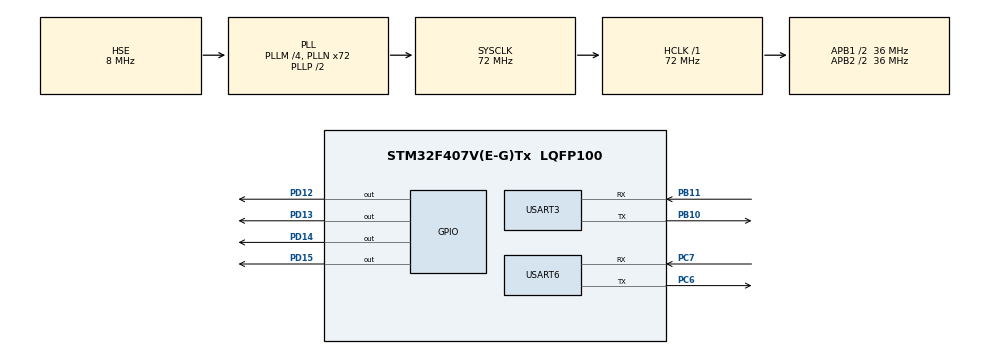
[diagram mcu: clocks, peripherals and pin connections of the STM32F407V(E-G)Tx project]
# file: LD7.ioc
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Mcu.Family=STM32F4
Mcu.Name=STM32F407V(E-G)Tx
Mcu.Package=LQFP100
NVIC.PriorityGroup=NVIC_PRIORITYGROUP_0
NVIC.TIM2_IRQn=true\:0\:0\:false\:true\:true\:3\:true\:true\:true
NVIC.USART3_IRQn=true\:0\:0\:false\:true\:true\:1\:true\:true\:true
NVIC.USART6_IRQn=true\:0\:0\:false\:true\:true\:2\:true\:true\:true
PA13.Mode=Trace_Asynchronous_SW
PA13.Signal=SYS_JTMS-SWDIO
PA14.Mode=Trace_Asynchronous_SW
PA14.Signal=SYS_JTCK-SWCLK
PB10.Mode=Asynchronous
PB10.Signal=USART3_TX
PB11.Mode=Asynchronous
PB11.Signal=USART3_RX
PB3.Mode=Trace_Asynchronous_SW
PB3.Signal=SYS_JTDO-SWO
PC6.Mode=Asynchronous
PC6.Signal=USART6_TX
PC7.Mode=Asynchronous
PC7.Signal=USART6_RX
PD12.Signal=GPIO_Output
PD13.Signal=GPIO_Output
PD14.Signal=GPIO_Output
PD15.Signal=GPIO_Output
PH0-OSC_IN.Mode=HSE-External-Clock-Source
PH0-OSC_IN.Signal=RCC_OSC_IN
PH1-OSC_OUT.Mode=HSE-External-Clock-Source
PH1-OSC_OUT.Signal=RCC_OSC_OUT
ProjectManager.HeapSize=0x200
ProjectManager.StackSize=0x400
ProjectManager.TargetToolchain=STM32CubeIDE
RCC.48MHZClocksFreq_Value=20571428.57142857
RCC.AHBFreq_Value=72000000
RCC.APB1CLKDivider=RCC_HCLK_DIV2
RCC.APB1Freq_Value=36000000
RCC.APB1TimFreq_Value=72000000
RCC.APB2CLKDivider=RCC_HCLK_DIV2
RCC.APB2Freq_Value=36000000
RCC.APB2TimFreq_Value=72000000
RCC.CortexFreq_Value=72000000
RCC.HCLKFreq_Value=72000000
RCC.HSE_VALUE=8000000
RCC.HSI_VALUE=16000000
RCC.PLLM=4
RCC.PLLN=72
RCC.PLLQ=7
RCC.PLLSourceVirtual=RCC_PLLSOURCE_HSE
RCC.SYSCLKFreq_VALUE=72000000
RCC.SYSCLKSource=RCC_SYSCLKSOURCE_PLLCLK
RCC.VCOOutputFreq_Value=144000000
TIM2.Period=2000
TIM2.Prescaler=36000-1
USART3.VirtualMode=VM_ASYNC
USART6.VirtualMode=VM_ASYNC
VP_TIM2_VS_ClockSourceINT.Mode=Internal
board=STM32F407G-DISC1

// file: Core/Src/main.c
/* USER CODE BEGIN Header */
/**
  ******************************************************************************
  * @file           : main.c
  * @brief          : Main program body
  ******************************************************************************
  * @attention
  *
  * Copyright (c) 2024 STMicroelectronics.
  * All rights reserved.
  *
  * This software is licensed under terms that can be found in the LICENSE file
  * in the root directory of this software component.
  * If no LICENSE file comes with this software, it is provided AS-IS.
  *
  ******************************************************************************
  */
/* USER CODE END Header */
#include "main.h"

TIM_HandleTypeDef htim2;

UART_HandleTypeDef huart3;
UART_HandleTypeDef huart6;

void SystemClock_Config(void);
static void MX_GPIO_Init(void);
static void MX_USART3_UART_Init(void);
static void MX_USART6_UART_Init(void);
static void MX_TIM2_Init(void);
static void MX_NVIC_Init(void);

int main(void)
{

  /* MCU Configuration--------------------------------------------------------*/

  /* Reset of all peripherals, Initializes the Flash interface and the Systick. */
  HAL_Init();

  /* Configure the system clock */
  SystemClock_Config();

  /* Initialize all configured peripherals */
  MX_GPIO_Init();
  MX_USART3_UART_Init();
  MX_USART6_UART_Init();
  MX_TIM2_Init();

  /* Initialize interrupts */
  MX_NVIC_Init();
  /* USER CODE BEGIN 2 */
  HAL_TIM_Base_Start_IT(&htim2);
  uint8_t txData[] = {0x01,0x03,0x07,0x0F};
  uint8_t rxData;
  uint8_t i = 0;
  /* USER CODE END 2 */

  /* Infinite loop */
  /* USER CODE BEGIN WHILE */
  while (1)
  {
//	  if(i<3){
//	 	  i ++;
//	 	  }else
//	 	  {
//	 		  i = 0;
//	 	  }
//
//
//	         HAL_UART_Transmit(&huart3, &txData[i], 1, 1000);
//	  HAL_UART_Receive(&huart6, &rxData, 1, 8);
//	         // Transmit received data via USART6
//	       //  HAL_GPIO_TogglePin(GPIOD, GPIO_PIN_12);
//	         GPIOD->ODR &= 0x00000000;
//	         GPIOD->ODR |= (rxData << 12);
//	         HAL_Delay(1000);
//	  if(rxData == 0xFF)
//	  {
//		  HAL_GPIO_TogglePin(GPIOD, GPIO_PIN_15);
//	  }
    /* USER CODE END WHILE */

  }
}

void SystemClock_Config(void)
{
  RCC_OscInitTypeDef RCC_OscInitStruct = {0};
  RCC_ClkInitTypeDef RCC_ClkInitStruct = {0};

  /** Configure the main internal regulator output voltage
  */
  __HAL_RCC_PWR_CLK_ENABLE();
  __HAL_PWR_VOLTAGESCALING_CONFIG(PWR_REGULATOR_VOLTAGE_SCALE1);

  /** Initializes the RCC Oscillators according to the specified parameters
  * in the RCC_OscInitTypeDef structure.
  */
  RCC_OscInitStruct.OscillatorType = RCC_OSCILLATORTYPE_HSE;
  RCC_OscInitStruct.HSEState = RCC_HSE_BYPASS;
  RCC_OscInitStruct.PLL.PLLState = RCC_PLL_ON;
  RCC_OscInitStruct.PLL.PLLSource = RCC_PLLSOURCE_HSE;
  RCC_OscInitStruct.PLL.PLLM = 4;
  RCC_OscInitStruct.PLL.PLLN = 72;
  RCC_OscInitStruct.PLL.PLLP = RCC_PLLP_DIV2;
  RCC_OscInitStruct.PLL.PLLQ = 7;
  if (HAL_RCC_OscConfig(&RCC_OscInitStruct) != HAL_OK)
  {
    Error_Handler();
  }

  /** Initializes the CPU, AHB and APB buses clocks
  */
  RCC_ClkInitStruct.ClockType = RCC_CLOCKTYPE_HCLK|RCC_CLOCKTYPE_SYSCLK
                              |RCC_CLOCKTYPE_PCLK1|RCC_CLOCKTYPE_PCLK2;
  RCC_ClkInitStruct.SYSCLKSource = RCC_SYSCLKSOURCE_PLLCLK;
  RCC_ClkInitStruct.AHBCLKDivider = RCC_SYSCLK_DIV1;
  RCC_ClkInitStruct.APB1CLKDivider = RCC_HCLK_DIV2;
  RCC_ClkInitStruct.APB2CLKDivider = RCC_HCLK_DIV2;

  if (HAL_RCC_ClockConfig(&RCC_ClkInitStruct, FLASH_LATENCY_2) != HAL_OK)
  {
    Error_Handler();
  }
}

/**
  * @brief NVIC Configuration.
  * @retval None
  */
static void MX_NVIC_Init(void)
{
  /* USART3_IRQn interrupt configuration */
  HAL_NVIC_SetPriority(USART3_IRQn, 0, 0);
  HAL_NVIC_EnableIRQ(USART3_IRQn);
  /* USART6_IRQn interrupt configuration */
  HAL_NVIC_SetPriority(USART6_IRQn, 0, 0);
  HAL_NVIC_EnableIRQ(USART6_IRQn);
  /* TIM2_IRQn interrupt configuration */
  HAL_NVIC_SetPriority(TIM2_IRQn, 0, 0);
  HAL_NVIC_EnableIRQ(TIM2_IRQn);
}

static void MX_TIM2_Init(void)
{

  TIM_ClockConfigTypeDef sClockSourceConfig = {0};
  TIM_MasterConfigTypeDef sMasterConfig = {0};

  htim2.Instance = TIM2;
  htim2.Init.Prescaler = 36000-1;
  htim2.Init.CounterMode = TIM_COUNTERMODE_UP;
  htim2.Init.Period = 2000;
  htim2.Init.ClockDivision = TIM_CLOCKDIVISION_DIV1;
  htim2.Init.AutoReloadPreload = TIM_AUTORELOAD_PRELOAD_DISABLE;
  if (HAL_TIM_Base_Init(&htim2) != HAL_OK)
  {
    Error_Handler();
  }
  sClockSourceConfig.ClockSource = TIM_CLOCKSOURCE_INTERNAL;
  if (HAL_TIM_ConfigClockSource(&htim2, &sClockSourceConfig) != HAL_OK)
  {
    Error_Handler();
  }
  sMasterConfig.MasterOutputTrigger = TIM_TRGO_RESET;
  sMasterConfig.MasterSlaveMode = TIM_MASTERSLAVEMODE_DISABLE;
  if (HAL_TIMEx_MasterConfigSynchronization(&htim2, &sMasterConfig) != HAL_OK)
  {
    Error_Handler();
  }

}

static void MX_USART3_UART_Init(void)
{

  huart3.Instance = USART3;
  huart3.Init.BaudRate = 115200;
  huart3.Init.WordLength = UART_WORDLENGTH_8B;
  huart3.Init.StopBits = UART_STOPBITS_1;
  huart3.Init.Parity = UART_PARITY_NONE;
  huart3.Init.Mode = UART_MODE_TX_RX;
  huart3.Init.HwFlowCtl = UART_HWCONTROL_NONE;
  huart3.Init.OverSampling = UART_OVERSAMPLING_16;
  if (HAL_UART_Init(&huart3) != HAL_OK)
  {
    Error_Handler();
  }

}

static void MX_USART6_UART_Init(void)
{

  huart6.Instance = USART6;
  huart6.Init.BaudRate = 115200;
  huart6.Init.WordLength = UART_WORDLENGTH_8B;
  huart6.Init.StopBits = UART_STOPBITS_1;
  huart6.Init.Parity = UART_PARITY_NONE;
  huart6.Init.Mode = UART_MODE_TX_RX;
  huart6.Init.HwFlowCtl = UART_HWCONTROL_NONE;
  huart6.Init.OverSampling = UART_OVERSAMPLING_16;
  if (HAL_UART_Init(&huart6) != HAL_OK)
  {
    Error_Handler();
  }

}

static void MX_GPIO_Init(void)
{
  GPIO_InitTypeDef GPIO_InitStruct = {0};

  /* GPIO Ports Clock Enable */
  __HAL_RCC_GPIOH_CLK_ENABLE();
  __HAL_RCC_GPIOB_CLK_ENABLE();
  __HAL_RCC_GPIOD_CLK_ENABLE();
  __HAL_RCC_GPIOC_CLK_ENABLE();
  __HAL_RCC_GPIOA_CLK_ENABLE();

  /*Configure GPIO pin Output Level */
  HAL_GPIO_WritePin(GPIOD, GPIO_PIN_12|GPIO_PIN_13|GPIO_PIN_14|GPIO_PIN_15, GPIO_PIN_RESET);

  /*Configure GPIO pins : PD12 PD13 PD14 PD15 */
  GPIO_InitStruct.Pin = GPIO_PIN_12|GPIO_PIN_13|GPIO_PIN_14|GPIO_PIN_15;
  GPIO_InitStruct.Mode = GPIO_MODE_OUTPUT_PP;
  GPIO_InitStruct.Pull = GPIO_NOPULL;
  GPIO_InitStruct.Speed = GPIO_SPEED_FREQ_LOW;
  HAL_GPIO_Init(GPIOD, &GPIO_InitStruct);

}

void Error_Handler(void)
{
  __disable_irq();
  while (1)
  {
  }
}
